# TC37XPD register map
Vendor: Infineon; Series: ATVMC; File version: 100
CPU: other r0p0, little endian, MPU, FPU, vendor SysTick, 4 interrupt priority bits
Registers are 32-bit, read-write, reset 0x0 unless marked. A register's access mark holds for its fields unless they carry their own. Offsets are from the block's base; [hi:lo] are bit positions; {n}, {i} and the like mark numbered series.

## IOM
Base 0xF0035000
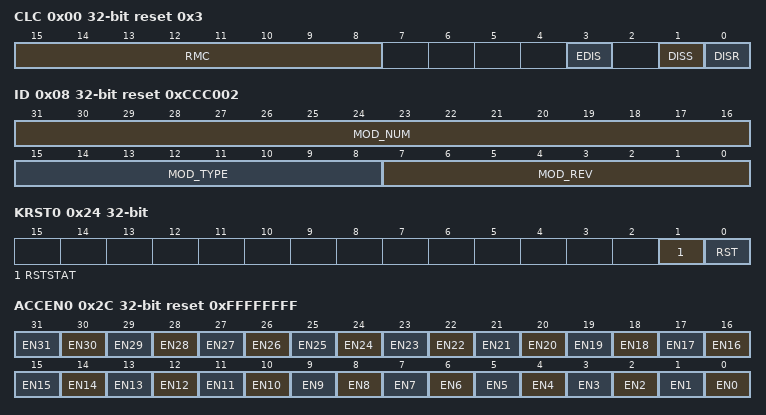
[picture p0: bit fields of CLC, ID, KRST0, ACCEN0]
0x00 CLC access per field reset 0x3 — IOM Clock Control Register resetvalue={Application Reset:0x3}
  [15:8] RMC rw — 8 bit Clock Divider Value in RUN Mode RMC
  [3] EDIS rw — Sleep Mode Enable Control EDIS. Used to control module 8217 s sleep mode.
  [1] DISS ro — Module Disable Status Bit DISS. Bit indicates the current status of the module.
  [0] DISR rw — Module Disable Request Bit DISR. Used for enable disable control of the module.
0x08 ID ro reset 0xCCC002 — IOM Identification Register resetvalue={Application Reset:0x0CCC002}
  [31:16] MOD_NUM — Module Number Value MOD NUM. This bit field defines the identification number for the IOM.
  [15:8] MOD_TYPE — Module Number Value MOD TYPE. This bit field defines the module as a 32 bit module C0 H
  [7:0] MOD_REV — Module Revision Number MOD REV. MOD REV defines the Module revision number.
0x1C KRSTCLR wo — IOM Kernel Reset Status Clear Register resetvalue={Application Reset:0x0}
  [0] CLR — Kernel Reset Status Clear CLR. Read always as 0.
0x20 KRST1 — IOM Kernel Reset Register 1 resetvalue={Application Reset:0x0}
  [0] RST — Kernel Reset RST. This reset bit can be used to request for a kernel reset. The kernel reset will be executed if the reset bits of both kernel reset registers is set. The RST bit will be cleared re set to xb4 0 xb4 by the BPI FPI after the kernel reset was executed.
0x24 KRST0 access per field — IOM Kernel Reset Register 0 resetvalue={Application Reset:0x0}
  [1] RSTSTAT ro — Kernel Reset Status RSTSTAT. This bit indicates wether a kernel reset was executed or not. This bit is set by the BPI FPI after the execution of a kernel reset in the same clock cycle both reset bits. This bit can be cleared by writing with xb4 1 xb4 to the CLR bit in the related KRSTCLR register.
  [0] RST rw — Kernel Reset RST. This reset bit can be used to request for a kernel reset. The kernel reset will be executed if the reset bits of both kernel registers are set. The RST bit will be cleared re set to xb4 0 xb4 by the BPI FPI after the kernel reset was executed.
0x2C ACCEN0 reset 0xFFFFFFFF — IOM Access Enable Register 0 resetvalue={Application Reset:0x0FFFFFFFF}
  [n] EN{n} (n=0..31) — Access Enable for Master TAG ID 31 EN31. This bit enables write access to the module kernel addresses for transactions with the Master TAG ID n
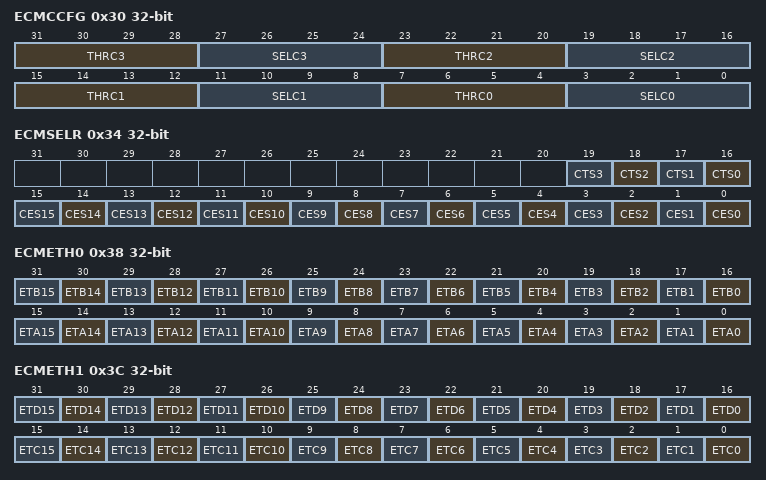
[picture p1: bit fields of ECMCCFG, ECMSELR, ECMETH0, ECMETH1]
0x30 ECMCCFG — IOM Event Combiner Module Counter Configuration Register resetvalue={Application Reset:0x0}
  [31:28] THRC3 — Channel Event Counter Threshold. This bit field determines the threshold count value. Upon the counter meeting the threshold the counter event output becomes active high for one clock cycle and the count is reset to zero.
  [27:24] SELC3 — Event Channel Select. This bit field determines which channel event output is to be routed to counter C3.
  [23:20] THRC2 — Channel Event Counter Threshold. This bit field determines the threshold count value. Upon the counter meeting the threshold the counter event output becomes active high for one clock cycle and the count is reset to zero.
  [19:16] SELC2 — Event Channel Select . This bit field determines which channel event output is to be routed to counter C2.
  [15:12] THRC1 — Channel Event Counter Threshold . This bit field determines the threshold count value. Upon the counter meeting the threshold the counter event output becomes active high for one clock cycle and the count is reset to zero.
  [11:8] SELC1 — Event Channel Select . This bit field determines which channel event output is to be routed to counter C1.
  [7:4] THRC0 — Channel Event Counter Threshold. This bit field determines the threshold count value. Upon the counter meeting the threshold the counter event output becomes active high for one clock cycle and the count is reset to zero.
  [3:0] SELC0 — Event Channel Select. This bit field determines which channel event output is to be routed to counter C0.
0x34 ECMSELR — IOM Event Combiner Module Global Event Selection Register resetvalue={Application Reset:0x0}
  [n+16] CTS{n} (n=0..3) — Accumulated Cou3ted Event Combiner Selection CTS3. The setting of individual bitfields determines the inclusion of the respective channel event counter output 1 of 4 in the generation of the global event.
  [n] CES{n} (n=0..15) — Eve15t Combiner Selection CES15. The setting of individual bitfields determines the inclusion of the respective channel event in the generation of the global event.
0x38 ECMETH0 — IOM Event Combiner Module Event Trigger History Register 0 resetvalue={Application Reset:0x0}
  [n+16] ETB{n} (n=0..15) — LAM 0 15 Eve15t Trigger Activity previous ETA0 15 ETB15. Contains the previous contents of ETA0 15 prior to being updated.
  [n] ETA{n} (n=0..15) — LAM 0 15 Eve15t Trigger Activity last ETA15. Contains the status of the event trigger outputs for each of the LAM blocks for the last generated event s .
0x3C ECMETH1 — IOM Event Combiner Module Event Trigger History Register 1 resetvalue={Application Reset:0x0}
  [n+16] ETD{n} (n=0..15) — LAM 0 15 Eve15t Trigger Activity previous contents of ETC0 15 OR ed with the previous value of ETD0 15 ETD15. Contains the previous content of ETC0 15 OR ed with the previous value of ETD0 15.
  [n] ETC{n} (n=0..15) — LAM 0 15 Eve15t Trigger Activity previous ETB0 15 ETC15. Contains the previous contents of ETB0 15 prior to being updated.
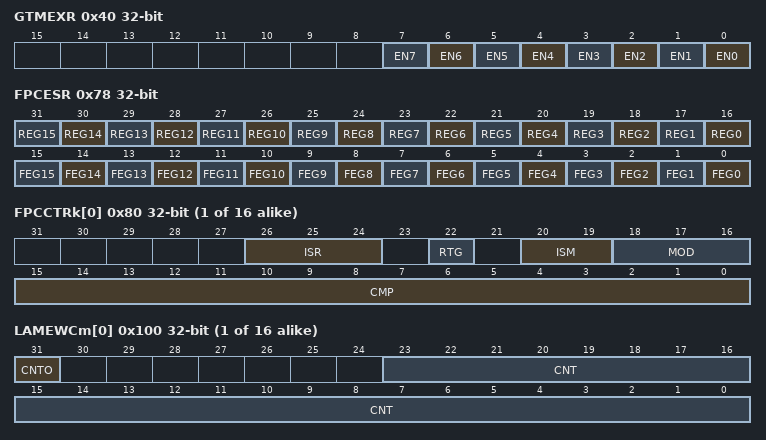
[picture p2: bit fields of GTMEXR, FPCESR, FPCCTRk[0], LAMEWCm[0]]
0x40 GTMEXR — IOM GTM Input EXOR Combiner Selection Register resetvalue={Application Reset:0x0}
  [n] EN{n} (n=0..7) — GTM input {n} selection for EXOR combiner EN{n}
0x78 FPCESR — IOM Filter and Prescaler Channels Rising Falling Edge Status Register resetvalue={Application Reset:0x0}
  [n+16] REG{n} (n=0..15) — Rising Edge Glitch Flag for FPC15 REG15
  [n] FEG{n} (n=0..15) — Falling Edge Glitch Flag for FPC15 FEG15
{0x80+4i} FPCCTRk[{i}] (i=0..15) — IOM Filter and Prescaler Channel Control Register 0 resetvalue={Application Reset:0x0}
  [26:24] ISR — Reference Input Signal Selection for Filter Prescaler Channel k ISR. ISR select the reference signal that goes to the reference input REF of the Logic Analyzer Module.
  [22] RTG — Reset Timer behavior for Filter Prescaler Channel k on Glitch RTG. This bit is effective in Delayed Debounce Filter Mode only.
  [20:19] ISM — Monitor Input Signal Selection for Filter Prescaler Channel k ISM. ISM selects the monitor signal that goes to the monitor input MON of the Logic Analyzer Module.
  [18:16] MOD — Operation Mode Selection for Filter Prescaler Channel k MOD
  [15:0] CMP — Threshold Value of Filter Prescaler Channel k CMP. CMP is the 16 bit threshold value that is compared with the 16 bit timer value FPCTIMk.TIM.
{0xC0+4i} FPCTIMk[{i}] (i=0..15) — IOM Filter and Prescaler Channel Timer Register 0 resetvalue={Application Reset:0x0}
  [15:0] TIM — Timer Value of Filter and Prescaler Channel k TIM. This bit bitfield shows the values of the timer of the Filter and Prescaler Channel. Writing to TIM will result in its content being set to its reset value.
{0x100+4i} LAMEWCm[{i}] (i=0..15) — IOM Logic Analyzer Module Event Window Count Status Register 0 resetvalue={Application Reset:0x0}
  [31] CNTO — Count Overflow Flag LAM block m CNTO. This bit field provides the information wether the count has reached its maximum value.
  [23:0] CNT — Event Window Count Value LAM block m CNT. The count value of the event window attained coincident with an event occurring.
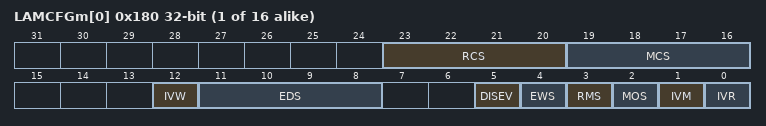
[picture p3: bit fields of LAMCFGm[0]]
{0x180+4i} LAMCFGm[{i}] (i=0..15) — IOM Logic Analyzer Module Configuration Register 0 resetvalue={Application Reset:0x0}
  [23:20] RCS — Reference Input Signal Selection LAM block m RCS. This bit field determines which FPC mux block k reference output signal is to be used for LAM block m.
  [19:16] MCS — Monitor Input Signal Selection LAM block m MCS. This bit field determines which FPC mux block k monitor output signal is to be used for LAM block m.
  [12] IVW — Invert Event Window LAM block m IVW. This bit field determines whether the event window polarity is inverted or not.
  [11:8] EDS — Event Window Active Edge Selection LAM block m EDS. This bit field determines which active edges of the monitor and reference signals are used for the event window generation.
  [5] DISEV — Disable Events LAM block m DISEV. This bit field allows to suppress alarm outputs from LAM block m to the ECM. Except for sending alarms to the ECM all other effects of an alarm condition being detected for instance setting LAMEWCm.CNT to the value of the counter will still take place inside LAM block m.
  [4] EWS — Event Window Select LAM block m EWS. This bit field determines whether the event window generation is from the monitor or reference signal.
  [3] RMS — Runmode Select LAM block m RMS. This bit field determines whether the event window generation is free running or gated with the monitor or reference.
  [2] MOS — Monitor Source Select LAM block m MOS. This bit field determines whether the monitor signal from the FPC monitor channel is sourced directly or compared EXOR x2019 d with the reference signal from the FPC reference channel for the event compare.
  [1] IVM — Invert Monitor LAM block m IVM. This bit field determines whether the monitor signal from the FPC monitor channel is inverted or not.
  [0] IVR — Invert Reference LAM block m IVR. This bit field determines whether the reference signal from the FPC reference channel is inverted or not.
{0x1C0+4i} LAMEWSm[{i}] (i=0..15) — IOM Logic Analyzer Module Event Window Configuration Register 0 resetvalue={Application Reset:0x0}
  [23:0] THR — Event Window Count Threshold THR. This bit field contains the value of the counter at which the event window becomes active before optional inversion .
